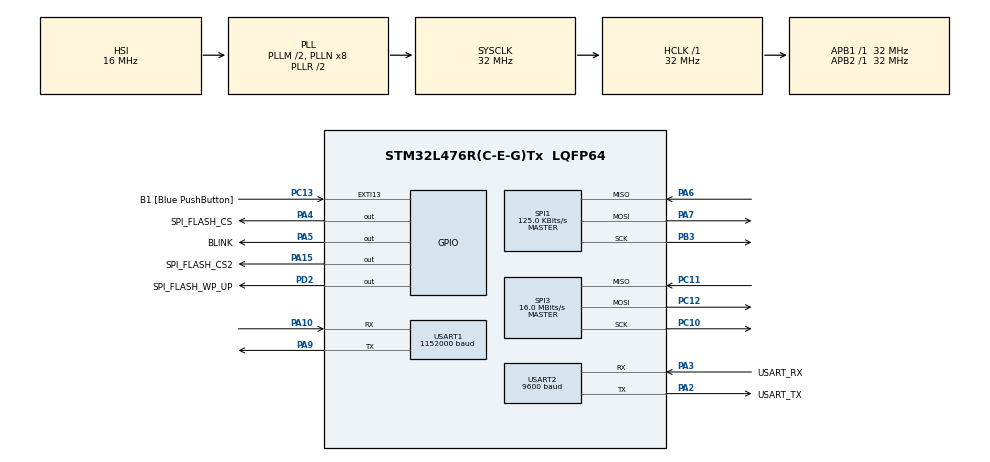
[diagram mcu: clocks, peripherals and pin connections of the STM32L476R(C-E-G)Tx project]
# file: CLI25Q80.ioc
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Dma.Request0=USART2_RX
Dma.USART2_RX.0.Direction=DMA_PERIPH_TO_MEMORY
Dma.USART2_RX.0.Instance=DMA1_Channel6
Dma.USART2_RX.0.MemDataAlignment=DMA_MDATAALIGN_BYTE
Dma.USART2_RX.0.MemInc=DMA_MINC_ENABLE
Dma.USART2_RX.0.Mode=DMA_CIRCULAR
Dma.USART2_RX.0.PeriphDataAlignment=DMA_PDATAALIGN_BYTE
Dma.USART2_RX.0.PeriphInc=DMA_PINC_DISABLE
Dma.USART2_RX.0.Priority=DMA_PRIORITY_MEDIUM
Mcu.Family=STM32L4
Mcu.Name=STM32L476R(C-E-G)Tx
Mcu.Package=LQFP64
NVIC.DMA1_Channel6_IRQn=true\:0\:0\:false\:false\:true\:false\:true\:true
NVIC.PriorityGroup=NVIC_PRIORITYGROUP_4
PA10.Mode=Asynchronous
PA10.Signal=USART1_RX
PA13\ (JTMS-SWDIO).GPIO_Label=TMS
PA13\ (JTMS-SWDIO).Mode=Serial_Wire
PA13\ (JTMS-SWDIO).Signal=SYS_JTMS-SWDIO
PA14\ (JTCK-SWCLK).GPIO_Label=TCK
PA14\ (JTCK-SWCLK).Mode=Serial_Wire
PA14\ (JTCK-SWCLK).Signal=SYS_JTCK-SWCLK
PA15\ (JTDI).GPIO_Label=SPI_FLASH_CS2
PA15\ (JTDI).GPIO_ModeDefaultOutputPP=GPIO_MODE_OUTPUT_PP
PA15\ (JTDI).GPIO_PuPd=GPIO_NOPULL
PA15\ (JTDI).GPIO_Speed=GPIO_SPEED_FREQ_MEDIUM
PA15\ (JTDI).PinState=GPIO_PIN_SET
PA15\ (JTDI).Signal=GPIO_Output
PA2.GPIO_Label=USART_TX
PA2.GPIO_Mode=GPIO_MODE_AF_PP
PA2.GPIO_PuPd=GPIO_NOPULL
PA2.GPIO_Speed=GPIO_SPEED_FREQ_VERY_HIGH
PA2.Mode=Asynchronous
PA2.Signal=USART2_TX
PA3.GPIO_Label=USART_RX
PA3.GPIO_Mode=GPIO_MODE_AF_PP
PA3.GPIO_PuPd=GPIO_NOPULL
PA3.GPIO_Speed=GPIO_SPEED_FREQ_VERY_HIGH
PA3.Mode=Asynchronous
PA3.Signal=USART2_RX
PA4.GPIO_Label=SPI_FLASH_CS
PA4.GPIO_Speed=GPIO_SPEED_FREQ_MEDIUM
PA4.PinState=GPIO_PIN_SET
PA4.Signal=GPIO_Output
PA5.GPIO_Label=BLINK
PA5.GPIO_ModeDefaultOutputPP=GPIO_MODE_OUTPUT_PP
PA5.GPIO_PuPd=GPIO_NOPULL
PA5.GPIO_Speed=GPIO_SPEED_FREQ_LOW
PA5.Signal=GPIO_Output
PA6.GPIO_Speed=GPIO_SPEED_FREQ_MEDIUM
PA6.Mode=Full_Duplex_Master
PA6.Signal=SPI1_MISO
PA7.GPIO_Speed=GPIO_SPEED_FREQ_MEDIUM
PA7.Mode=Full_Duplex_Master
PA7.Signal=SPI1_MOSI
PA9.Mode=Asynchronous
PA9.Signal=USART1_TX
PB3\ (JTDO-TRACESWO).GPIO_Speed=GPIO_SPEED_FREQ_MEDIUM
PB3\ (JTDO-TRACESWO).Mode=Full_Duplex_Master
PB3\ (JTDO-TRACESWO).Signal=SPI1_SCK
PC10.GPIO_Speed=GPIO_SPEED_FREQ_MEDIUM
PC10.Mode=Full_Duplex_Master
PC10.Signal=SPI3_SCK
PC11.GPIO_Speed=GPIO_SPEED_FREQ_MEDIUM
PC11.Mode=Full_Duplex_Master
PC11.Signal=SPI3_MISO
PC12.GPIO_Speed=GPIO_SPEED_FREQ_MEDIUM
PC12.Mode=Full_Duplex_Master
PC12.Signal=SPI3_MOSI
PC13.GPIO_Label=B1 [Blue PushButton]
PC13.GPIO_ModeDefaultEXTI=GPIO_MODE_IT_FALLING
PC13.GPIO_PuPd=GPIO_NOPULL
PC13.Signal=GPXTI13
PC14-OSC32_IN\ (PC14).Signal=RCC_OSC32_IN
PC15-OSC32_OUT\ (PC15).Signal=RCC_OSC32_OUT
PD2.GPIO_Label=SPI_FLASH_WP_UP
PD2.GPIO_ModeDefaultOutputPP=GPIO_MODE_OUTPUT_PP
PD2.GPIO_PuPd=GPIO_NOPULL
PD2.GPIO_Speed=GPIO_SPEED_FREQ_MEDIUM
PD2.PinState=GPIO_PIN_SET
PD2.Signal=GPIO_Output
PH0-OSC_IN\ (PH0).Signal=RCC_OSC_IN
PH1-OSC_OUT\ (PH1).Signal=RCC_OSC_OUT
ProjectManager.HeapSize=0x1000
ProjectManager.StackSize=0x2000
ProjectManager.TargetToolchain=STM32CubeIDE
RCC.ADCFreq_Value=32000000
RCC.AHBFreq_Value=32000000
RCC.APB1Freq_Value=32000000
RCC.APB1TimFreq_Value=32000000
RCC.APB2Freq_Value=32000000
RCC.APB2TimFreq_Value=32000000
RCC.CortexFreq_Value=32000000
RCC.HCLKFreq_Value=32000000
RCC.HSE_VALUE=8000000
RCC.HSI_VALUE=16000000
RCC.LSE_VALUE=32768
RCC.MSI_VALUE=4000000
RCC.PLLM=2
RCC.PLLSourceVirtual=RCC_PLLSOURCE_HSI
RCC.PREFETCH_ENABLE=1
RCC.SYSCLKFreq_VALUE=32000000
RCC.SYSCLKSource=RCC_SYSCLKSOURCE_PLLCLK
RCC.USBFreq_Value=32000000
RCC.VCOOutputFreq_Value=64000000
SPI1.BaudRatePrescaler=SPI_BAUDRATEPRESCALER_256
SPI1.CLKPhase=SPI_PHASE_2EDGE
SPI1.CLKPolarity=SPI_POLARITY_HIGH
SPI1.CalculateBaudRate=125.0 KBits/s
SPI1.DataSize=SPI_DATASIZE_8BIT
SPI1.Direction=SPI_DIRECTION_2LINES
SPI1.Mode=SPI_MODE_MASTER
SPI1.TIMode=SPI_TIMODE_DISABLE
SPI1.VirtualType=VM_MASTER
SPI3.BaudRatePrescaler=SPI_BAUDRATEPRESCALER_2
SPI3.CLKPhase=SPI_PHASE_1EDGE
SPI3.CLKPolarity=SPI_POLARITY_LOW
SPI3.CalculateBaudRate=16.0 MBits/s
SPI3.DataSize=SPI_DATASIZE_8BIT
SPI3.Direction=SPI_DIRECTION_2LINES
SPI3.FirstBit=SPI_FIRSTBIT_MSB
SPI3.Mode=SPI_MODE_MASTER
SPI3.NSSPMode=SPI_NSS_PULSE_DISABLE
SPI3.VirtualType=VM_MASTER
USART1.BaudRate=1152000
USART1.Mode=MODE_TX_RX
USART1.VirtualMode-Asynchronous=VM_ASYNC
USART2.BaudRate=9600
USART2.VirtualMode-Asynchronous=VM_ASYNC
board=NUCLEO-L476RG

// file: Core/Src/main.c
/* USER CODE BEGIN Header */
/**
  ******************************************************************************
  * @file           : main.c
  * @brief          : Main program body
  ******************************************************************************
  * @attention
  *
  * Copyright (c) 2022 STMicroelectronics.
  * All rights reserved.
  *
  * This software is licensed under terms that can be found in the LICENSE file
  * in the root directory of this software component.
  * If no LICENSE file comes with this software, it is provided AS-IS.
  *
  ******************************************************************************
  */
/* USER CODE END Header */
#include "main.h"
#include "dma.h"
#include "spi.h"
#include "usart.h"
#include "gpio.h"

void SystemClock_Config(void);

int main(void)
{

  /* MCU Configuration--------------------------------------------------------*/

  /* Reset of all peripherals, Initializes the Flash interface and the Systick. */
  HAL_Init();

  /* Configure the system clock */
  SystemClock_Config();

  /* Initialize all configured peripherals */
  MX_GPIO_Init();
  MX_DMA_Init();
  MX_USART2_UART_Init();
  MX_SPI3_Init();
  MX_SPI1_Init();
  MX_USART1_UART_Init();
  /* USER CODE BEGIN 2 */
  userApp();
  /* USER CODE END 2 */

  /* Infinite loop */
  while (1)
  {

    /* USER CODE BEGIN 3 */

	  HAL_GPIO_TogglePin(fromMX(BLINK));
	  HAL_Delay(150);

  }
  /* USER CODE END 3 */
}

void SystemClock_Config(void)
{
  RCC_OscInitTypeDef RCC_OscInitStruct = {0};
  RCC_ClkInitTypeDef RCC_ClkInitStruct = {0};

  /** Configure the main internal regulator output voltage
  */
  if (HAL_PWREx_ControlVoltageScaling(PWR_REGULATOR_VOLTAGE_SCALE1) != HAL_OK)
  {
    Error_Handler();
  }

  /** Initializes the RCC Oscillators according to the specified parameters
  * in the RCC_OscInitTypeDef structure.
  */
  RCC_OscInitStruct.OscillatorType = RCC_OSCILLATORTYPE_HSI;
  RCC_OscInitStruct.HSIState = RCC_HSI_ON;
  RCC_OscInitStruct.HSICalibrationValue = RCC_HSICALIBRATION_DEFAULT;
  RCC_OscInitStruct.PLL.PLLState = RCC_PLL_ON;
  RCC_OscInitStruct.PLL.PLLSource = RCC_PLLSOURCE_HSI;
  RCC_OscInitStruct.PLL.PLLM = 2;
  RCC_OscInitStruct.PLL.PLLN = 8;
  RCC_OscInitStruct.PLL.PLLP = RCC_PLLP_DIV7;
  RCC_OscInitStruct.PLL.PLLQ = RCC_PLLQ_DIV2;
  RCC_OscInitStruct.PLL.PLLR = RCC_PLLR_DIV2;
  if (HAL_RCC_OscConfig(&RCC_OscInitStruct) != HAL_OK)
  {
    Error_Handler();
  }

  /** Initializes the CPU, AHB and APB buses clocks
  */
  RCC_ClkInitStruct.ClockType = RCC_CLOCKTYPE_HCLK|RCC_CLOCKTYPE_SYSCLK
                              |RCC_CLOCKTYPE_PCLK1|RCC_CLOCKTYPE_PCLK2;
  RCC_ClkInitStruct.SYSCLKSource = RCC_SYSCLKSOURCE_PLLCLK;
  RCC_ClkInitStruct.AHBCLKDivider = RCC_SYSCLK_DIV1;
  RCC_ClkInitStruct.APB1CLKDivider = RCC_HCLK_DIV1;
  RCC_ClkInitStruct.APB2CLKDivider = RCC_HCLK_DIV1;

  if (HAL_RCC_ClockConfig(&RCC_ClkInitStruct, FLASH_LATENCY_1) != HAL_OK)
  {
    Error_Handler();
  }
}

void Error_Handler(void)
{
  __disable_irq();
  while (1)
  {
  }
}
